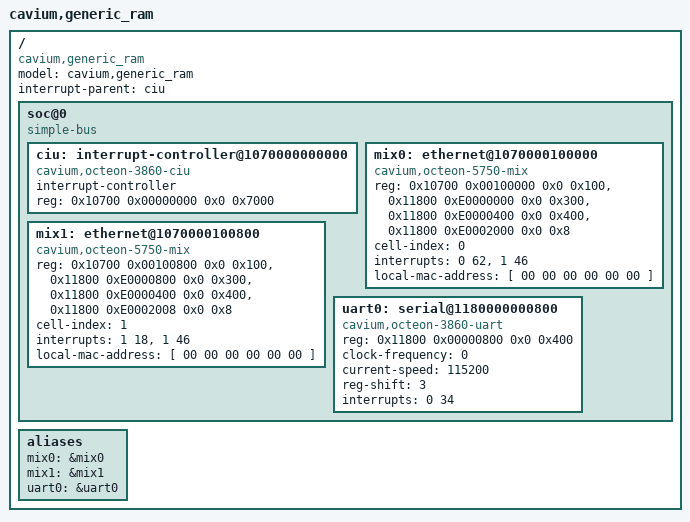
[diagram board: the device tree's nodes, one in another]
/dts-v1/;
/*
 * Cavium Generic RAM
 */
/ {
	model = "cavium,generic_ram";
	compatible = "cavium,generic_ram";
	#address-cells = <2>;
	#size-cells = <2>;
	interrupt-parent = <&ciu>;

	soc@0 {
		compatible = "simple-bus";
		#address-cells = <2>;
		#size-cells = <2>;
		ranges; /* Direct mapping */

		ciu: interrupt-controller@1070000000000 {
			compatible = "cavium,octeon-3860-ciu";
			interrupt-controller;
			/* Interrupts are specified by two parts:
			 * 1) Controller register (0 or 1)
			 * 2) Bit within the register (0..63)
			 */
			#interrupt-cells = <2>;
			reg = <0x10700 0x00000000 0x0 0x7000>;
		};


		mix0: ethernet@1070000100000 {
			compatible = "cavium,octeon-5750-mix";
			reg = <0x10700 0x00100000 0x0 0x100>, /* MIX */
			      <0x11800 0xE0000000 0x0 0x300>, /* AGL */
			      <0x11800 0xE0000400 0x0 0x400>, /* AGL_SHARED  */
			      <0x11800 0xE0002000 0x0 0x8>;   /* AGL_PRT_CTL */
			cell-index = <0>;
			interrupts = <0 62>, <1 46>;
			local-mac-address = [ 00 00 00 00 00 00 ];
		};

		mix1: ethernet@1070000100800 {
			compatible = "cavium,octeon-5750-mix";
			reg = <0x10700 0x00100800 0x0 0x100>, /* MIX */
			      <0x11800 0xE0000800 0x0 0x300>, /* AGL */
			      <0x11800 0xE0000400 0x0 0x400>, /* AGL_SHARED  */
			      <0x11800 0xE0002008 0x0 0x8>;   /* AGL_PRT_CTL */
			cell-index = <1>;
			interrupts = <1 18>, < 1 46>;
			local-mac-address = [ 00 00 00 00 00 00 ];
		};

		uart0: serial@1180000000800 {
			compatible = "cavium,octeon-3860-uart","ns16550";
			reg = <0x11800 0x00000800 0x0 0x400>;
			clock-frequency = <0>;
			current-speed = <115200>;
			reg-shift = <3>;
			interrupts = <0 34>;
		};
	};

	aliases {
		mix0 = &mix0;
		mix1 = &mix1;
		uart0 = &uart0;
	};
 };
